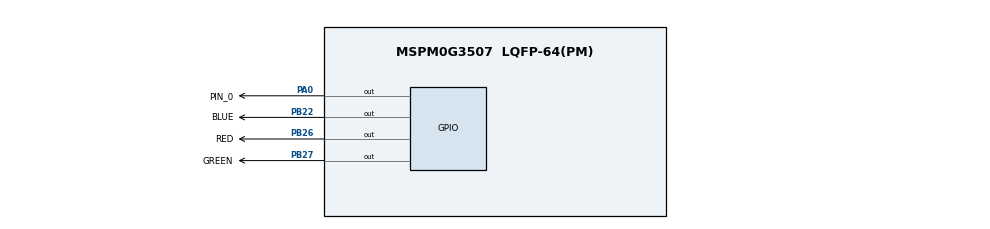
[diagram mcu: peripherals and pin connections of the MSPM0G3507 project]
//@cliArgs --device "MSPM0G350X" --package "LQFP-64(PM)" --part "Default"
//@v2CliArgs --device "MSPM0G3507" --package "LQFP-64(PM)"
// @cliArgs --board /ti/boards/LP_MSPM0G3507 --rtos nortos

/**
 * Import the modules used in this configuration.
 */
const ADC12         = scripting.addModule("/ti/driverlib/ADC12", {}, false);
const ADC121        = ADC12.addInstance();
const Board         = scripting.addModule("/ti/driverlib/Board");
const GPIO          = scripting.addModule("/ti/driverlib/GPIO", {}, false);
const GPIO1         = GPIO.addInstance();
const SYSCTL        = scripting.addModule("/ti/driverlib/SYSCTL");
const ProjectConfig = scripting.addModule("/ti/project_config/ProjectConfig");

/**
 * Write custom configuration values to the imported modules.
 */
ADC121.$name                      = "ADC12_0";
ADC121.sampClkDiv                 = "DL_ADC12_CLOCK_DIVIDE_8";
ADC121.repeatMode                 = true;
ADC121.enabledInterrupts          = ["DL_ADC12_INTERRUPT_MEM0_RESULT_LOADED"];
ADC121.sampCnt                    = 1;
ADC121.enabledDMATriggers         = ["DL_ADC12_DMA_MEM0_RESULT_LOADED"];
ADC121.sampleTime0                = "198 us";
ADC121.peripheral.$assign         = "ADC0";
ADC121.peripheral.adcPin0.$assign = "PA27";
ADC121.adcPin0Config.$name        = "ti_driverlib_gpio_GPIOPinGeneric0";

GPIO1.$name                         = "LED";
GPIO1.associatedPins.create(4);
GPIO1.associatedPins[0].$name       = "RED";
GPIO1.associatedPins[0].pin.$assign = "PB26";
GPIO1.associatedPins[1].$name       = "BLUE";
GPIO1.associatedPins[1].pin.$assign = "PB22";
GPIO1.associatedPins[2].$name       = "GREEN";
GPIO1.associatedPins[2].pin.$assign = "PB27";
GPIO1.associatedPins[3].$name       = "PIN_0";
GPIO1.associatedPins[3].pin.$assign = "PA0";

SYSCTL.MFPCLKEn              = true;
SYSCTL.forceDefaultClkConfig = true;
SYSCTL.clockTreeEn           = true;

ProjectConfig.genLibCMSIS        = true;
ProjectConfig.migrationCondition = true;
